# STM32H573 register map
File version: 0.4
CPU: CM33 r0p0, little endian, MPU, FPU, 4 interrupt priority bits
Registers are 32-bit, read-write, reset 0x0 unless marked. A register's access mark holds for its fields unless they carry their own. Offsets are from the block's base; [hi:lo] are bit positions; {n}, {i} and the like mark numbered series.

## PSSI — Parallel synchronous slave interface
Base 0x4202C400
Same registers: SEC_PSSI 0x5202C400
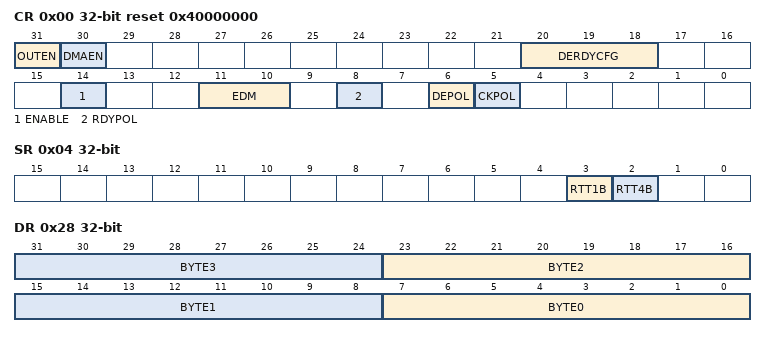
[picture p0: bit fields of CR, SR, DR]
0x00 CR reset 0x40000000 — PSSI control register
  [31] OUTEN — Data direction selection bit
  [30] DMAEN — DMA enable bit
  [20:18] DERDYCFG — Data enable and ready configuration When the PSSI_RDY function is mapped to the PSSI_DE pin (settings 101 or 111), it is still the RDYPOL bit which determines its polarity. Similarly, when the PSSI_DE function is mapped to the PSSI_RDY pin (settings 110 or 111), it is still the DEPOL bit which determines its polarity.
  [14] ENABLE — PSSI enable The contents of the FIFO are flushed when ENABLE is cleared to 0. Note: When ENABLE=1, the content of PSSI_CR must not be changed, except for the ENABLE bit itself. All configuration bits can change as soon as ENABLE changes from 0 to 1. The DMA controller and all PSSI configuration registers must be programmed correctly before setting the ENABLE bit to 1. The ENABLE bit and the DCMI ENABLE bit (bit 15 of DCMI_CR) must not be set to 1 at the same time.
  [11:10] EDM — Extended data mode
  [8] RDYPOL — Ready (PSSI_RDY) polarity This bit indicates the level on the PSSI_RDY pin when the data are not valid on the parallel interface.
  [6] DEPOL — Data enable (PSSI_DE) polarity This bit indicates the level on the PSSI_DE pin when the data are not valid on the parallel interface.
  [5] CKPOL — Parallel data clock polarity This bit configures the capture edge of the parallel clock or the edge used for driving outputs, depending on OUTEN.
0x04 SR ro — PSSI status register
  [3] RTT1B — FIFO is ready to transfer one byte
  [2] RTT4B — FIFO is ready to transfer four bytes
0x08 RIS ro — PSSI raw interrupt status register
  [1] OVR_RIS — Data buffer overrun/underrun raw interrupt status This bit is cleared by writing a 1 to the OVR_ISC bit in PSSI_ICR.
0x0C IER — PSSI interrupt enable register
  [1] OVR_IE — Data buffer overrun/underrun interrupt enable
0x10 MIS ro — PSSI masked interrupt status register
  [1] OVR_MIS — Data buffer overrun/underrun masked interrupt status This bit is set to 1 only when PSSI_IER/OVR_IE and PSSI_RIS/OVR_RIS are both set to 1.
0x14 ICR wo — PSSI interrupt clear register
  [1] OVR_ISC — Data buffer overrun/underrun interrupt status clear Writing this bit to 1 clears the OVR_RIS bit in PSSI_RIS.
0x28 DR — PSSI data register
  [8n+7:8n] BYTE{n} (n=0..3) — Data byte {n}

## VREFBUF — Voltage reference buffer
Base 0x44007400
Same registers: SEC_VREFBUF 0x54007400
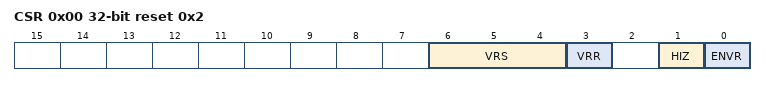
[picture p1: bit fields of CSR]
0x00 CSR access per field reset 0x2 — VREFBUF control and status register
  [6:4] VRS rw — Voltage reference scale These bits select the value generated by the voltage reference buffer. VRS = 000: VREFBUF0 voltage selected. VRS = 001: VREFBUF1 voltage selected. VRS = 010: VREFBUF2 voltage selected. VRS = 011: VREFBUF3 voltage selected. Others: Reserved Note: Refer to the product datasheet for each VREFBUFx voltage setting value. The software can program this bitfield only when the VREFBUF is disabled (ENVR=0).
  [3] VRR ro — Voltage reference buffer ready
  [1] HIZ rw — High impedance mode This bit controls the analog switch to connect or not the VREF+ pin. Refer to for the mode descriptions depending on ENVR bit configuration.
  [0] ENVR rw — Voltage reference buffer mode enable This bit is used to enable the voltage reference buffer mode.
0x04 CCR (reset mask 0xFFFFFF00) — VREFBUF calibration control register
  [5:0] TRIM — Trimming code The TRIM code is a 6-bit unsigned data (minimum 000000, maximum 111111) that is set and updated according the mechanism described below. Reset: TRIM[5:0] is automatically initialized with the VRS = 0 trimming value stored in the Flash memory during the production test. VRS change: TRIM[5:0] is automatically initialized with the trimming value (corresponding to VRS setting) stored in the Flash memory during the production test. Write in TRIM[5:0]: User can modify the TRIM[5:0] with an arbitrary value. This is permanently disabling the control of the trimming value with VRS (until the device is reset). Note: If the user application performs the trimming, the trimming code must start from 000000 to 111111 in ascending order.

## WWDG — System window watchdog
Base 0x40002C00
Same registers: SEC_WWDG 0x50002C00
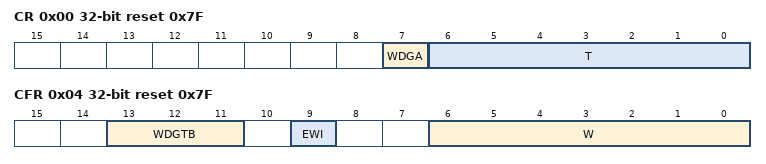
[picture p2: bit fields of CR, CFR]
0x00 CR reset 0x7F — WWDG control register
  [7] WDGA — Activation bit This bit is set by software and only cleared by hardware after a reset. When WDGA = 1, the watchdog can generate a reset.
  [6:0] T — 7-bit counter (MSB to LSB) These bits contain the value of the watchdog counter, decremented every (4096 x 2WDGTB[2:0]) PCLK cycles. A reset is produced when it is decremented from 0x40 to 0x3F (T6 becomes cleared).
0x04 CFR reset 0x7F — WWDG configuration register
  [13:11] WDGTB — Timer base The timebase of the prescaler can be modified as follows:
  [9] EWI — Early wakeup interrupt When set, an interrupt occurs whenever the counter reaches the value 0x40. This interrupt is only cleared by hardware after a reset.
  [6:0] W — 7-bit window value These bits contain the window value to be compared with the down-counter.
0x08 SR — WWDG status register
  [0] EWIF — Early wakeup interrupt flag This bit is set by hardware when the counter has reached the value 0x40. It must be cleared by software by writing ‘0’. Writing ‘1’ has no effect. This bit is also set if the interrupt is not enabled.
